# SAMA7D65D2GN8 register map
Vendor: Microchip Technology; Series: SAMA7D6; File version: 0
Registers are 32-bit, read-write, reset 0x0 unless marked. A register's access mark holds for its fields unless they carry their own. Offsets are from the block's base; [hi:lo] are bit positions; lines under a group give offsets from that group; {n}, {i} and the like mark numbered series.

## SPDIFRX — Sony/Philips Digital Interface Receiver
Base 0xE280C000
0x00 CR wo — Control Register
  [0] SWRST — Software Reset
    0=No effect; 1=Resets the SPDIF receiver
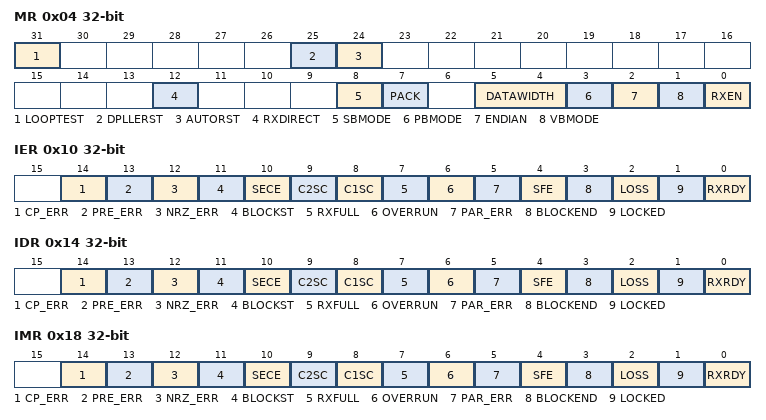
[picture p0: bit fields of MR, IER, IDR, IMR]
0x04 MR — Mode Register
  [31] LOOPTEST — SPDIFTX to SPDIFRX Loop Test
    0=DISABLE (SPDIFRX decodes the external received line (SPDIF_RX).); 1=ENABLE (The SPDIFTX internal output line is decoded by SPDIFRX.)
  [25] DPLLERST — DPLL Error Automatic Restart
    0=NOACTION (An abnormal parity error detected on DPLL settings (automatically calculated each time the SPDIFRX is enabled) may lead to preamble recovery loss and after a pattern of 16 consecutive preamble errors the DPLL controller will be re-initialized to realign the data recovery (if AUTORST=1).); 1=RESTART_ON_ERR (As soon as a parity check error is detected on DPLL settings, the DPLL is reinitialized, providing a faster realignment time in case of abnormal internal error in the DPLL controller.)
  [24] AUTORST — Consecutive Preamble Error Threshold Automatic Restart
    0=NOACTION (No action whatever the number of consecutive preamble errors found during the period where SPDIFRX_RSR.ULOCK=0.); 1=UNLOCK_ON_PRE_ERR (If 16 consecutive preamble errors are detected, the clock recovery circuitry is restarted.)
  [12] RXDIRECT — Receiver Direct Access Enable
    0=The SPDIFRX Receiver Holding register must be read by software or DMA to get the audio samples from the SPDIF line; 1=Asynchronous Sample Rate Converter (ASRC) can be directly loaded with the audio samples recovered from the SPDIF line without software or DMA intervention
  [8] SBMODE — Start of Block Bit Mode
    0=ALWAYS_LOAD (Whatever the preamble code , the sample is loaded in FIFO.); 1=DISCARD (The sample is loaded in FIFO only if an Start of block is detected.)
  [7] PACK — Packed Data Mode in Receive Holding Register
    0=DISABLED (Each read of SPDIFRX_RHR contains 1 sample and additional information (validity bit, parity bit, user data bit, channel status bit, byte 0 bit 1 of channel status and type of frame carrying the sample).); 1=ENABLED (The 32-bit SPDIFRX_RHR contains only payload data. Depending on the value of SPDIFRX_MR.DATAWIDTH, the alignment of data differs. This mode optimizes the amount of system memory required to manage the samples.)
  [5:4] DATAWIDTH — Sample Data Width
    0=24BIT (The complete data field is stored in FIFO.); 1=20BIT (Only the 20 MSB are stored in the FIFO.); 2=16BIT (Only the 16 MSB are stored in the FIFO.)
  [3] PBMODE — Parity Bit Mode
    0=PARCHECK (Parity check enabled on data payload.); 1=NOPARCHECK (There is no parity check on data payload.)
  [2] ENDIAN — Data Word Endian Mode
    0=LITTLE (Little-endian mode for 24-bit samples.); 1=BIG (Big-endian mode for 24-bit samples.)
  [1] VBMODE — Validity Bit Mode
    0=ALWAYS_LOAD (Whatever the validity bit value is, the sample is loaded in FIFO.); 1=DISCARD_IF_VB1 (The sample is loaded in FIFO only if the validity bit equals 0.)
  [0] RXEN — SPDIF Receive Enable
    0=DISABLE (SPDIF receiver is disabled.); 1=ENABLE (SPDIF receiver is enabled.)
0x10 IER wo — Interrupt Enable Register
  [14] CP_ERR — 16 Consecutive Preamble Errors Interrupt Enable
  [13] PRE_ERR — Preamble Error (code violation) Enable
  [12] NRZ_ERR — NRZ Biphase Mark Error in payload data (code violation) Enable
  [11] BLOCKST — Start of Block Interrupt Enable
  [10] SECE — Security Report Interrupt Enable
  [9] C2SC — Bit 0 to 31 Channel 2 Status Change Interrupt Enable
  [8] C1SC — Bit 0 to 31 Channel 1 Status Change Interrupt Enable
  [7] RXFULL — Receiver FIFO Full Interrupt Enable
  [6] OVERRUN — FIFO Overrun, Interrupt Enable
  [5] PAR_ERR — Parity Bit Error Interrupt Enable
  [4] SFE — Sampling Frequency Change Event Interrupt Enable
  [3] BLOCKEND — End of Block Interrupt Enable
  [2] LOSS — Loss of Signal Activity While Locked Interrupt Enable
  [1] LOCKED — Receiver Synchronized Interrupt Enable
  [0] RXRDY — Receive Data Ready Interrupt Enable
0x14 IDR wo — Interrupt Disable Register
  [14] CP_ERR — 16 Consecutive Preamble Errors Interrupt Disable
  [13] PRE_ERR — Preamble Error (code violation) Disable
  [12] NRZ_ERR — NRZ Biphase Mark Error in payload data (code violation) Disable
  [11] BLOCKST — Start of Block Interrupt Disable
  [10] SECE — Security Report Interrupt Disable
  [9] C2SC — Bit 0 to 31 Channel 2 Status Change Interrupt Disable
  [8] C1SC — Bit 0 to 31 Channel 1 Status Change Interrupt Disable
  [7] RXFULL — Receiver FIFO Full Interrupt Disable
  [6] OVERRUN — FIFO Overrun, Interrupt Disable
  [5] PAR_ERR — Parity Bit Error Interrupt Disable
  [4] SFE — Sampling Frequency Change Event Interrupt Disable
  [3] BLOCKEND — End of Block Interrupt Disable
  [2] LOSS — Loss of Signal Activity While Locked Interrupt Disable
  [1] LOCKED — Receiver Synchronized Interrupt Disable
  [0] RXRDY — Receive Data Ready Interrupt Disable
0x18 IMR ro — Interrupt Mask Register
  [14] CP_ERR — 16 Consecutive Preamble Errors Interrupt Mask
  [13] PRE_ERR — Preamble Error (code violation) Interrupt Mask
  [12] NRZ_ERR — NRZ Biphase Mark Error in payload data (code violation) Interrupt Mask
  [11] BLOCKST — Start of Block Interrupt Interrupt Mask
  [10] SECE — Security Report Interrupt Interrupt Mask
  [9] C2SC — Bit 0 to 31 Channel 2 Status Change Interrupt Mask
  [8] C1SC — Bit 0 to 31 Channel 1 Status Change Interrupt Mask
  [7] RXFULL — Receiver FIFO Full Interrupt Mask
  [6] OVERRUN — FIFO Overrun, Interrupt Mask
  [5] PAR_ERR — Parity Bit Error Interrupt Mask
  [4] SFE — Sampling Frequency Change Event Interrupt Mask
  [3] BLOCKEND — End of Block Interrupt Mask
  [2] LOSS — Loss of Signal Activity While Locked Interrupt Mask
  [1] LOCKED — Receiver Synchronized Interrupt Mask
  [0] RXRDY — Receive Data Ready Interrupt Mask
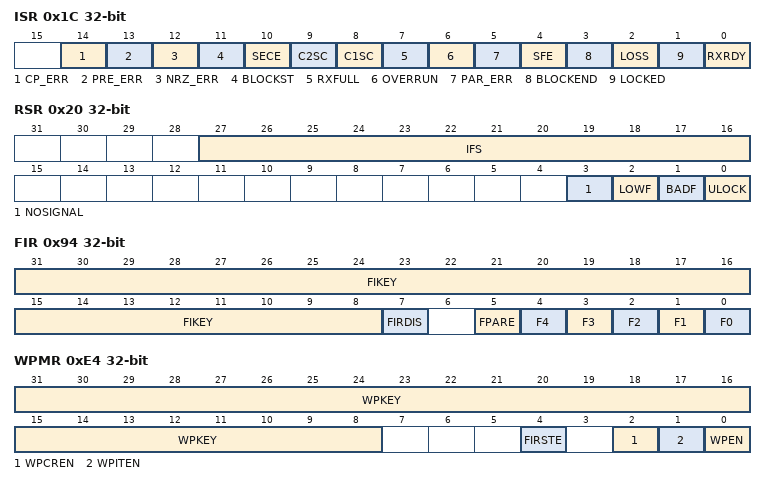
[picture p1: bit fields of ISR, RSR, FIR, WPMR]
0x1C ISR ro — Interrupt Status Register
  [14] CP_ERR — 16 Consecutive Preamble Errors Interrupt Status (cleared on read)
  [13] PRE_ERR — Preamble Error (code violation) Status (cleared on read)
  [12] NRZ_ERR — NRZ Biphase Mark Error in payload data (code violation) Status (cleared on read)
  [11] BLOCKST — Start of Block Interrupt Status (cleared on read)
  [10] SECE — Security Report Interrupt Status (cleared on read)
  [9] C2SC — Bit 0 to 31 Channel 2 Status Change (cleared on read)
  [8] C1SC — Bit 0 to 31 Channel 1 Status Change (cleared on read)
  [7] RXFULL — Receiver FIFO Full Interrupt Status (cleared on read)
  [6] OVERRUN — FIFO Overrun, Interrupt Status (cleared on read)
  [5] PAR_ERR — Parity Bit Error Interrupt Status (cleared on read)
  [4] SFE — Sampling Frequency Change Event Interrupt Status (cleared on read)
  [3] BLOCKEND — End of Block Interrupt Status (cleared on read)
  [2] LOSS — Loss of Signal Activity While Locked Interrupt Status (cleared on read)
  [1] LOCKED — Receiver Synchronized Interrupt Status (cleared on read)
  [0] RXRDY — Receive Data Ready Interrupt Status (cleared when reading SPDIFRX_RHR)
0x20 RSR ro — Status Register
  [27:16] IFS — Image of Sampling Frequency
  [3] NOSIGNAL — No Signal on Receive Line
    0=The receiver is synchronized or searching for receive line frequency or preambles; 1=The receiver is not able to find any activity (no edge) on RX line
  [2] LOWF — Low Clock Frequency provided on GCLK Clock
    0=The receiver is synchronized or the receiver is determining the sample frequency of the receive line or searching preambles; 1=The receiver is not able to recover the protocol because the GCLK clock frequency is lower than the minimum required
  [1] BADF — Bad Format Detected on SPDIF RX Line
    0=The receiver is synchronized or the receiver is searching for SPDIF receive line frequency or preambles; 1=The receiver is not able to detect a SPDIF format on the receive line
  [0] ULOCK — Unlocked Receiver
    0=The receiver is synchronized and loads data, or the receiver is disabled; 1=The receiver is not locked because it is searching for SPDIF receive line frequency or preambles. See BADF, LOWF, and NOSIGNAL for reasons of unlocked state.
0x24 RHR ro — Holding Register
  [31:0] DATA — Channel 1 and 2 Data
{0x30+0x30*i} SPDIFRX_CH[{i}] (i=0..1) group
  {0x0+4j} CHxSR[{j}] (j=0..5) ro — Channel X Status Register x
    [31:0] CHSTATUS — Channel X Status Data
  {0x18+4j} CHxUD[{j}] (j=0..5) ro — Channel X User Data Register x
    [31:0] CHUSERDATA — Channel X User Data
0x94 FIR — Fault Injection Register
  [31:8] FIKEY — Fault Injection Access Key
    0x534649=PASSWD (Writing any other value in this field aborts the write operation.)
  [7] FIRDIS — Fault Injection Register Disable
    0=NO_EFFECT; 1=ACTIVE (Disables the fault injection until the next hardware reset. The command is valid only if the flag SPDIFRX_WPSR.SEQE=0 and the other bits are cleared (F0=F1=F2=F3=F4=FPARE=0).)
  [5] FPARE — Single Fault for SPDIFRX Configuration Register
    0=NO_EFFECT; 1=INJECT_CLEAR (Injects a single fault on the configuration register if the SPDIFRX is disabled (for security reason), the flag SPDIFRX_WPSR.PARE raises and the flag SPDIFRX_ISR.SECE =1. Clears the fault if it has been previously injected.)
  [4] F4 — Single Fault for SPDIFRX Write Protection Mode Register (SPDIFRX_WPMR.WPCREN)
    0=Clears the fault. The flag SPDIFRX_WPSR.SDEE is automatically cleared.; 1=Injects a single fault on the reinforced safety for the SPDIFRX_WPMR.WPCREN bit if 0x534649 ('SFI' in ASCII) is written in the FIKEY field at the same time. The SPDIFRX remains in the same state, the flag SPDIFRX_ISR.SECE=1 and the flag SPDIFRX_WPSR.SDEE=1.
  [3] F3 — Single Fault for SPDIFRX Write Protection Mode Register (SPDIFRX_WPMR.WPITEN)
    0=Clears the fault. The flag SPDIFRX_WPSR.SDEE is automatically cleared.; 1=Injects a single fault on the reinforced safety for the SPDIFRX_WPMR.WPITEN bit if 0x534649 ('SFI' in ASCII) is written in the FIKEY field at the same time. The SPDIFRX remains in the same state, the flag SPDIFRX_ISR.SECE=1 and the flag SPDIFRX_WPSR.SDEE=1.
  [2] F2 — Single Fault for SPDIFRX Write Protection Mode Register (SPDIFRX_WPMR.WPEN)
    0=Clears the fault. The flag SPDIFRX_WPSR.SDEE is automatically cleared.; 1=Injects a single fault on the reinforced safety for the SPDIFRX_WPMR.WPEN bit if 0x534649 ('SFI' in ASCII) is written in the FIKEY field at the same time. The SPDIFRX remains in the same state, the flag SPDIFRX_ISR.SECE=1 and the flag SPDIFRX_WPSR.SDEE=1.
  [1] F1 — Single Fault for SPDIFRX Mode Register (SPDIFRX_MR.RXDIRECT)
    0=Clears the fault. The flag SPDIFRX_WPSR.SDEE is automatically cleared.; 1=Injects a single fault on the reinforced safety for the SPDIFRX_MR.RXDIRECT bit if 0x534649 ('SFI' in ASCII) is written in the FIKEY field at the same time. The SPDIFRX remains in the same state, the flag SPDIFRX_ISR.SECE=1 and the flag SPDIFRX_WPSR.SDEE=1.
  [0] F0 — Single Fault for SPDIFRX Mode Register (SPDIFRX_MR.RXEN)
    0=Clears the fault. The flag SPDIFRX_WPSR.SDEE is automatically cleared.; 1=Injects a single fault on the reinforced safety for the SPDIFRX_MR.RXEN bit if 0x534649 ('SFI' in ASCII) is written in the FIKEY field at the same time. The SPDIFRX remains in the same state, the flag SPDIFRX_ISR.SECE=1 and the flag SPDIFRX_WPSR.SDEE=1.
0xE4 WPMR — Write Protection Mode Register
  [31:8] WPKEY — Write Protection Key
    0x535044=PASSWD (Writing any other value in this field aborts the write operation of the WPEN, WPITEN and WPCREN bits. Always reads at 0.)
  [4] FIRSTE — First Error Report Enable
    0=The last write protection violation source is reported in SPDIFRX_WPSR.WPSRC and the last software control error type is reported in SPDIFRX_WPSR.SWETYP. The SPDIFRX_ISR.SECE flag is set at the first error occurrence within a series.; 1=Only the first write protection violation source is reported in SPDIFRX_WPSR.WPSRC and only the first software control error type is reported in SPDIFRX_WPSR.SWETYP. The SPDIFRX_ISR.SECE flag is set at the first error occurrence within a series.
  [2] WPCREN — Write Protection Control Register Enable
    0=Disables the write protection on the Control register (SPDIFRX_CR) if WPKEY corresponds to 0x535044; 1=Enables the write protection on the Control register (SPDIFRX_CR) if WPKEY corresponds to 0x535044
  [1] WPITEN — Write Protection Interrupt Enable
    0=Disables the write protection on Interrupt registers if WPKEY corresponds to 0x535044; 1=Enables the write protection on Interrupt registers if WPKEY corresponds to 0x535044
  [0] WPEN — Write Protection Enable
    0=Disables the write protection if WPKEY corresponds to 0x535044 ('SPD' in ASCII); 1=Enables the write protection is enabled. All accesses to configuration registers are canceled and generate an error in the SPDIFRX_WPSR register.
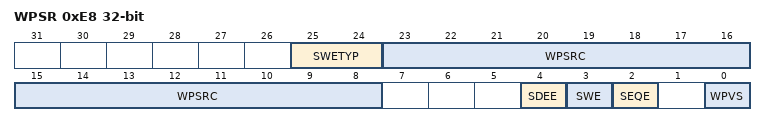
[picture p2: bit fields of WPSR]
0xE8 WPSR ro — Write Protection Status Register
  [25:24] SWETYP — Software Error Type (cleared on read)
    0=READ_WO (A write-only register has been read (warning).); 1=WRITE_RO (A write access has been performed on a read-only register (Warning).); 2=UNDEF_RW (Access to an undefined address (warning).)
  [23:8] WPSRC — Write Protection Violation Source
  [4] SDEE — Single or Dual Event Error (cleared by reconfiguring the faulty registers or by clearing the error via SPDIFRX_FIR)
    0=No single or dual error detected in SPDIFRX_MR.RXEN bits; 1=Single or dual error detected in SPDIFRX_MR.RXEN bits. If a single error event occurred, the error is filtered and has no effect on SPDIFRX.
  [3] SWE — Software Control Error (cleared on read)
    0=No software error has occurred since the last read of SPDIFRX_WPSR; 1=A software error has occurred since the last read of SPDIFRX_WPSR. The field SWETYP details the type of software abnormal access; the associated incorrect software access is reported in the field WPSRC (if WPVS=0).
  [2] SEQE — Internal Sequencer Error (cleared on read)
    0=No peripheral internal sequencer error has occurred since the last read of SPDIFRX_WPSR; 1=A peripheral internal sequencer error has occurred since the last read of SPDIFRX_WPSR. This flag can only be set under abnormal operating conditions.
  [0] WPVS — Write Protection Violation Status (cleared on read)
    0=No write protection violation has occurred since the last read of SPDIFRX_WPSR; 1=A write protection violation has occurred since the last read of SPDIFRX_WPSR. If this violation is an unauthorized attempt to write a protected register, the associated violation is reported into field WPSRC.
